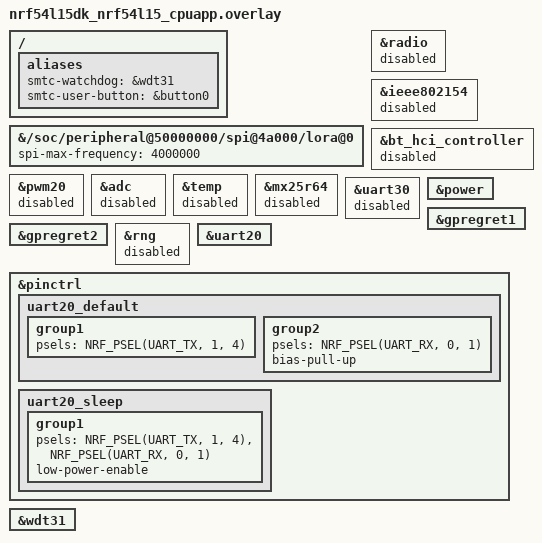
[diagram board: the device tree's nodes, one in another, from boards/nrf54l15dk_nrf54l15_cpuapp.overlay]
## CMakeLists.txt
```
# Copyright (c) 2024 Semtech Corporation
# SPDX-License-Identifier: Apache-2.0

cmake_minimum_required(VERSION 3.13.1)

find_package(Zephyr REQUIRED HINTS $ENV{ZEPHYR_BASE})
project(wifi_region_detection)

target_sources(app PRIVATE
  ${CMAKE_CURRENT_SOURCE_DIR}/src/main.c
  ${CMAKE_CURRENT_SOURCE_DIR}/../geolocation/src/geolocation_bsp.c
  ${ZEPHYR_USP_MODULE_DIR}/examples/main_examples/geolocation/wifi_region_detection/wifi_region_finder.c
)

zephyr_include_directories(
  ${CMAKE_CURRENT_SOURCE_DIR}/src
  ${ZEPHYR_USP_MODULE_DIR}/examples/main_examples/geolocation/wifi_region_detection
)
```

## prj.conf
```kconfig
# Copyright (c) 2024 Semtech Corporation
# SPDX-License-Identifier: Apache-2.0
# ------------------------------ Debug options ------------------------------

CONFIG_DEBUG=y
CONFIG_NO_OPTIMIZATIONS=y
CONFIG_DEBUG_OPTIMIZATIONS=y
CONFIG_DEBUG_THREAD_INFO=y
CONFIG_DCACHE=n

# ------------------------------ General configuration ------------------------------

CONFIG_USE_SEGGER_RTT=n

# stack size (Zephyr boilerplate + 2048 required by Semtech)
CONFIG_MAIN_STACK_SIZE=8192

# some operations will be triggered from the system workq, so match above stack size
CONFIG_SYSTEM_WORKQUEUE_STACK_SIZE=8192

CONFIG_LOG=y
CONFIG_LOG_BACKEND_SHOW_COLOR=n # Set it to 'y' to enable color formatting on output messages
CONFIG_LOG_BUFFER_SIZE=4096

CONFIG_TEST_RANDOM_GENERATOR=y

CONFIG_PM_DEVICE=y

CONFIG_WATCHDOG=n

CONFIG_FLASH=y

# ------------------------------ Transceiver driver ----------------------------

CONFIG_LORA_BASICS_MODEM_DRIVERS=y
#CONFIG_LORA_BASICS_MODEM_DRIVERS_EVENT_TRIGGER_GLOBAL_THREAD=y
CONFIG_LORA_BASICS_MODEM_DRIVERS_EVENT_TRIGGER_NO_THREAD=y

# ------------------------------ LoRa Basics Modem -----------------------------

#CONFIG_LORA_BASICS_MODEM_LOG_LEVEL_DBG=y
CONFIG_LORA_BASICS_MODEM_LOG_VERBOSE=y

CONFIG_LORA_BASICS_MODEM_GEOLOCATION=y

# ------------------------------ USP -----------------------------
CONFIG_USP=y
CONFIG_USP_MAIN_THREAD=n
CONFIG_USP_LORA_BASICS_MODEM=y
```

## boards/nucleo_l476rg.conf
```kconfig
# Copyright (c) 2024 Semtech Corporation
# SPDX-License-Identifier: Apache-2.0

# ------------------------------ NUCLEO L476RG CLOCK DRIFT -----------------------------
CONFIG_CORTEX_M_SYSTICK=n
CONFIG_STM32_LPTIM_TIMER=y
CONFIG_CLOCK_CONTROL=y
CONFIG_PM=y
```

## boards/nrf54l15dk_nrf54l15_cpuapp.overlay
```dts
// /*
//  * Copyright (c) 2024 Semtech Corporation
//  *
//  * SPDX-License-Identifier: Apache-2.0
//  */

/ {
	aliases {
		smtc-watchdog = &wdt31;
		smtc-user-button = &button0;
	};
};

// Set SPI freq @4MHz
&{/soc/peripheral@50000000/spi@4a000/lora@0} {
	spi-max-frequency = < 4000000 >;
};

&radio {
	status = "disabled";
};

&ieee802154 {
	status = "disabled";
};

&bt_hci_controller {
	status = "disabled";
};

&pwm20 {
	status = "disabled";
};

&adc {
	status = "disabled";
};

&temp {
	status = "disabled";
};

&mx25r64 {
	status = "disabled";
};


// &rng_hci {
	//     status = "disabled";
// };

&uart30 {
	status = "disabled";
};

// &clock {
	//     status = "disabled"; //For some reason, disabling it increases power consumption
// };

&power {
	status = "okay";
};

&gpregret1 {
	status = "okay";
};

&gpregret2 {
	status = "okay";
};

&rng {
	status = "disabled";
};

// &spi00 {
	//     status = "disabled";
// };


&uart20 {
	status = "okay";
	// disable-rx; //Disabling RX allows a gain of ~200µA, totally disabling uart allows another gain of ~200µA
	// /delete-property/ hw-flow-control;
};

&pinctrl {
	uart20_default: uart20_default {
		group1 {
			psels = <NRF_PSEL(UART_TX, 1, 4)>
			// ,<NRF_PSEL(UART_RTS, 0, 2)>
			;
		};
		group2 {
			psels = <NRF_PSEL(UART_RX, 0, 1)> //DIO9 is mapped on RX
			// ,<NRF_PSEL(UART_CTS, 0, 3)>
			;
			bias-pull-up;
		};
	};

	uart20_sleep: uart20_sleep {
		group1 {
			psels = <NRF_PSEL(UART_TX, 1, 4)>,
					<NRF_PSEL(UART_RX, 0, 1)>
					// ,<NRF_PSEL(UART_RTS, 0, 2)>
					// ,<NRF_PSEL(UART_CTS, 0, 3)>
					;
			low-power-enable;
		};
	};
};

&wdt31 {
	status = "okay";
};
```

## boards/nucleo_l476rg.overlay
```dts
/*
 * Copyright (c) 2024 Semtech Corporation
 *
 * SPDX-License-Identifier: Apache-2.0
 */

/ {
        aliases {
                smtc-watchdog = &iwdg;
                smtc-user-button = &user_button;
        };
};

&spi3 {
        status = "disabled";
};

&iwdg {
        status = "disabled";
};

&arduino_spi {
        /delete-property/ overrun-character;
        // Uncomment those 3 lines to activate DMA on STM32L4
        // dmas = <&dma1 3 1 (STM32_DMA_PERIPH_TX | STM32_DMA_PRIORITY_HIGH)>,
        //        <&dma1 2 1 (STM32_DMA_PERIPH_RX | STM32_DMA_PRIORITY_HIGH)>;
        // dma-names = "tx", "rx";
};

// Uncomment those 3 lines to activate DMA on STM32L4
// &dma1 {
//         status = "okay";
// };

&arduino_i2c {
        /delete-property/ zephyr,concat-buf-size;
};

&lptim1 {
	clocks = <&rcc STM32_CLOCK_BUS_APB1 0x80000000>,
		 <&rcc STM32_SRC_LSE LPTIM1_SEL(3)>;
	status = "okay";
};
```

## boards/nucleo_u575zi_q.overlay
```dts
/*
 * Copyright (c) 2024 Semtech Corporation
 *
 * SPDX-License-Identifier: Apache-2.0
 */


/ {
	aliases {
		smtc-watchdog = &iwdg;
		smtc-user-button = &user_button;
	};
};

&i2c1 {
	status = "disabled";
};

&i2c2 {
	status = "disabled";
};

&lptim1 {
	status = "disabled";
};

&timers3 {
	status = "disabled";
};

&timers4 {
	status = "disabled";
};

&dac1 {
	status = "disabled";
};

&adc1 {
	status = "disabled";
};

&adc4 {
	status = "disabled";
};

&fdcan1 {
	status = "disabled";
};

&usbotg_fs {
	status = "disabled";
};

&usart2 {
	status = "disabled";
};

&iwdg {
	status = "disabled";
};

&wwdg {
	status = "disabled";
};

&arduino_spi {
	/delete-property/ overrun-character;
};

&arduino_i2c {
    /delete-property/ zephyr,concat-buf-size;
};
```

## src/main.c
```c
/**
 * @file      main.c
 *
 * @brief     Application main
 *
 * The Clear BSD License
 * Copyright Semtech Corporation 2025. All rights reserved.
 *
 * Redistribution and use in source and binary forms, with or without
 * modification, are permitted (subject to the limitations in the disclaimer
 * below) provided that the following conditions are met:
 *     * Redistributions of source code must retain the above copyright
 *       notice, this list of conditions and the following disclaimer.
 *     * Redistributions in binary form must reproduce the above copyright
 *       notice, this list of conditions and the following disclaimer in the
 *       documentation and/or other materials provided with the distribution.
 *     * Neither the name of the Semtech corporation nor the
 *       names of its contributors may be used to endorse or promote products
 *       derived from this software without specific prior written permission.
 *
 * NO EXPRESS OR IMPLIED LICENSES TO ANY PARTY'S PATENT RIGHTS ARE GRANTED BY
 * THIS LICENSE. THIS SOFTWARE IS PROVIDED BY THE COPYRIGHT HOLDERS AND
 * CONTRIBUTORS "AS IS" AND ANY EXPRESS OR IMPLIED WARRANTIES, INCLUDING, BUT
 * NOT LIMITED TO, THE IMPLIED WARRANTIES OF MERCHANTABILITY AND FITNESS FOR A
 * PARTICULAR PURPOSE ARE DISCLAIMED. IN NO EVENT SHALL SEMTECH CORPORATION BE
 * LIABLE FOR ANY DIRECT, INDIRECT, INCIDENTAL, SPECIAL, EXEMPLARY, OR
 * CONSEQUENTIAL DAMAGES (INCLUDING, BUT NOT LIMITED TO, PROCUREMENT OF
 * SUBSTITUTE GOODS OR SERVICES; LOSS OF USE, DATA, OR PROFITS; OR BUSINESS
 * INTERRUPTION) HOWEVER CAUSED AND ON ANY THEORY OF LIABILITY, WHETHER IN
 * CONTRACT, STRICT LIABILITY, OR TORT (INCLUDING NEGLIGENCE OR OTHERWISE)
 * ARISING IN ANY WAY OUT OF THE USE OF THIS SOFTWARE, EVEN IF ADVISED OF THE
 * POSSIBILITY OF SUCH DAMAGE.
 */

#include <zephyr/kernel.h>
#include <zephyr/logging/log.h>
#include <zephyr/drivers/gpio.h>
#include <zephyr/lorawan_lbm/lorawan_hal_init.h>

#include <smtc_modem_api.h>
#include <smtc_sw_platform_helper.h>
#include <smtc_rac_api.h>
#include <smtc_modem_geolocation_api.h>
#include <smtc_modem_utilities.h>
#define SMTC_HAL_DBG_TRACE_C
#include <smtc_hal_dbg_trace.h>
#include <wifi_region_finder.h>

LOG_MODULE_REGISTER( wifi_region_detection, LOG_LEVEL_INF );

/*
 * -----------------------------------------------------------------------------
 * --- PRIVATE CONSTANTS -------------------------------------------------------
 */

/**
 * Stack id value (multistacks modem is not yet available)
 */
#define STACK_ID 0

/**
 * @brief Watchdog counter reload value during sleep (The period must be lower than MCU watchdog
 * period (here 32s))
 */
#define WATCHDOG_RELOAD_PERIOD_MS ( 20000 )

/*
 * -----------------------------------------------------------------------------
 * --- PRIVATE TYPES -----------------------------------------------------------
 */

/*
 * -----------------------------------------------------------------------------
 * --- PRIVATE VARIABLES -------------------------------------------------------
 */

static wrf_region_score_t score = { 0 };

static const struct gpio_dt_spec rx_led = GPIO_DT_SPEC_GET( DT_PATH( leds, lr11xx_rx_led ), gpios );
static const struct gpio_dt_spec tx_led = GPIO_DT_SPEC_GET( DT_PATH( leds, lr11xx_tx_led ), gpios );

/*
 * -----------------------------------------------------------------------------
 * --- PRIVATE FUNCTIONS DECLARATION -------------------------------------------
 */

/**
 * @brief User callback for modem event
 *
 *  This callback is called every time an event ( see smtc_modem_event_t ) appears in the modem.
 *  Several events may have to be read from the modem when this callback is called.
 */
static void modem_event_callback( void );

/*
 * -----------------------------------------------------------------------------
 * --- PUBLIC FUNCTIONS DEFINITION ---------------------------------------------
 */

/**
 * @brief Example to flash the LR11xx firmware
 *
 */
int main( void )
{
    gpio_pin_configure_dt( &rx_led, GPIO_OUTPUT_INACTIVE );
    gpio_pin_configure_dt( &tx_led, GPIO_OUTPUT_INACTIVE );

    LOG_INF( "WiFi Region Detection example" );

    SMTC_SW_PLATFORM_INIT( );
    SMTC_SW_PLATFORM_VOID( smtc_rac_init( ) );
    // Call smtc_modem_init() after smtc_rac_init()
    // Init the modem and use modem_event_callback as event callback, please note that the callback will be
    // called immediately after the first call to smtc_modem_run_engine because of the reset detection
    SMTC_SW_PLATFORM_VOID( smtc_modem_init( &modem_event_callback ) );

    while( true )
    {
        uint32_t sleep_time_ms = smtc_modem_run_engine( );
        smtc_rac_run_engine( );
        if( smtc_rac_is_irq_flag_pending( ) )
        {
            continue;
        }
        k_sem_take( smtc_modem_hal_get_event_sem( ), K_MSEC( MIN( sleep_time_ms, WATCHDOG_RELOAD_PERIOD_MS ) ) );
    }

    return 0;
}

/*
 * -----------------------------------------------------------------------------
 * --- PRIVATE FUNCTIONS DEFINITION --------------------------------------------
 */

/**
 * @brief User callback for modem event
 *
 *  This callback is called every time an event ( see smtc_modem_event_t ) appears in the modem.
 *  Several events may have to be read from the modem when this callback is called.
 */
static void modem_event_callback( void )
{
    smtc_modem_event_t                      current_event;
    uint8_t                                 event_pending_count;
    uint8_t                                 stack_id = STACK_ID;
    smtc_modem_wifi_event_data_scan_done_t  wifi_scan_done_data;
    smtc_modem_wifi_event_data_terminated_t wifi_terminated_data;
    smtc_modem_region_t                     region_detected             = 0;
    uint8_t                                 region_detection_confidence = 0;

    // Continue to read modem event until all event has been processed
    do
    {
        // Read modem event
        smtc_modem_get_event( &current_event, &event_pending_count );

        switch( current_event.event_type )
        {
        case SMTC_MODEM_EVENT_RESET:
            SMTC_HAL_TRACE_INFO( "Event received: RESET\n" );
            if( check_lr11xx_fw_version( transceiver ) != true )
            {
                SMTC_HAL_TRACE_ERROR( "LR11xx firmware version is not compatible with this example\n" );
                break;
            }
            /* Initialize WiFi Region Finder */
            wrf_init( );
            SMTC_HAL_TRACE_PRINTF( "\n" );
            SMTC_HAL_TRACE_INFO( "-----------------------\n" );
            SMTC_HAL_TRACE_WARNING( "Estimated region: UNKNOWN\n" );
            SMTC_HAL_TRACE_INFO( "-----------------------\n" );
            SMTC_HAL_TRACE_PRINTF( "\n" );
            /* Set Wi-Fi send mode */
            smtc_modem_wifi_send_mode( stack_id, SMTC_MODEM_SEND_MODE_BYPASS );
            /* Program Wi-Fi scan */
            smtc_modem_wifi_set_scan_mode( stack_id, SMTC_MODEM_WIFI_SCAN_MODE_MAC_COUNTRY_CODE_SSID );
            smtc_modem_wifi_scan( stack_id, 0 );
            break;

        case SMTC_MODEM_EVENT_ALARM:
            SMTC_HAL_TRACE_INFO( "Event received: ALARM\n" );
            break;

        case SMTC_MODEM_EVENT_JOINED:
            SMTC_HAL_TRACE_INFO( "Event received: JOINED\n" );
            break;

        case SMTC_MODEM_EVENT_TXDONE:
            SMTC_HAL_TRACE_INFO( "Event received: TXDONE (%d)\n", current_event.event_data.txdone.status );
            SMTC_HAL_TRACE_INFO( "Transmission done\n" );
            break;

        case SMTC_MODEM_EVENT_DOWNDATA:
            SMTC_HAL_TRACE_INFO( "Event received: DOWNDATA\n" );
            break;

        case SMTC_MODEM_EVENT_JOINFAIL:
            SMTC_HAL_TRACE_INFO( "Event received: JOINFAIL\n" );
            SMTC_HAL_TRACE_WARNING( "Join request failed \n" );
            break;

        case SMTC_MODEM_EVENT_ALCSYNC_TIME:
            SMTC_HAL_TRACE_INFO( "Event received: TIME\n" );
            break;

        case SMTC_MODEM_EVENT_GNSS_SCAN_DONE:
            SMTC_HAL_TRACE_INFO( "Event received: GNSS_SCAN_DONE\n" );
            break;

        case SMTC_MODEM_EVENT_GNSS_TERMINATED:
            SMTC_HAL_TRACE_INFO( "Event received: GNSS_TERMINATED\n" );
            break;

        case SMTC_MODEM_EVENT_GNSS_ALMANAC_DEMOD_UPDATE:
            SMTC_HAL_TRACE_INFO( "Event received: GNSS_ALMANAC_DEMOD_UPDATE\n" );
            break;

        case SMTC_MODEM_EVENT_WIFI_SCAN_DONE:
            SMTC_HAL_TRACE_INFO( "Event received: WIFI_SCAN_DONE\n" );
            /* Get event data */
            smtc_modem_wifi_get_event_data_scan_done( stack_id, &wifi_scan_done_data );
            /* Analyze results with WiFi Region Finder */
            for( uint8_t j = 0; j < wifi_scan_done_data.nbr_results; ++j )
            {
                wifi_scan_single_result_t* result = &wifi_scan_done_data.results[j];

                const uint8_t* mac  = result->mac_address;
                const char*    ssid = ( const char* ) result->ssid_bytes;
                const char*    cc   = ( const char* ) result->country_code;

                wrf_process_ap( mac, ssid, cc, &score );
            }
            wrf_print_region_scores( &score );
            int ret = wrf_get_highest_score_region( &score, REGION_DETECT_SCORE_THRESHOLD, &region_detected,
                                                    &region_detection_confidence );
            SMTC_HAL_TRACE_PRINTF( "\n" );
            SMTC_HAL_TRACE_INFO( "-----------------------\n" );
            if( ret == 0 )
            {
                SMTC_HAL_TRACE_INFO( "Estimated region: %s with %d%% confidence\n", region_to_string( region_detected ),
                                     region_detection_confidence );
            }
            else
            {
                SMTC_HAL_TRACE_WARNING( "Estimated region: UNKNOWN\n" );
            }
            SMTC_HAL_TRACE_INFO( "-----------------------\n" );
            SMTC_HAL_TRACE_PRINTF( "\n" );
            break;

        case SMTC_MODEM_EVENT_WIFI_TERMINATED:
            SMTC_HAL_TRACE_INFO( "Event received: WIFI_TERMINATED\n" );
            // smtc_board_led_pulse( smtc_board_get_led_tx_mask( ), true, LED_PERIOD_MS );
            /* Get event data */
            smtc_modem_wifi_get_event_data_terminated( stack_id, &wifi_terminated_data );
            /* launch next scan */
            smtc_modem_wifi_scan( stack_id, 0 );
            break;

        case SMTC_MODEM_EVENT_LINK_CHECK:
            SMTC_HAL_TRACE_INFO( "Event received: LINK_CHECK\n" );
            break;

        case SMTC_MODEM_EVENT_CLASS_B_STATUS:
            SMTC_HAL_TRACE_INFO( "Event received: CLASS_B_STATUS\n" );
            break;

        default:
            SMTC_HAL_TRACE_ERROR( "Unknown event %u\n", current_event.event_type );
            break;
        }
    } while( event_pending_count > 0 );
}

/* --- EOF ------------------------------------------------------------------ */
```
